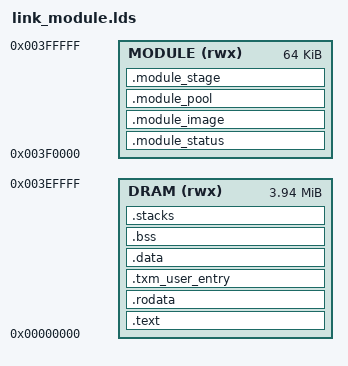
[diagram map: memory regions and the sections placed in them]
/***************************************************************************
 * Copyright (c) 2026 Eclipse ThreadX contributors
 *
 * This program and the accompanying materials are made available under the
 * terms of the MIT License which is available at
 * https://opensource.org/licenses/MIT.
 *
 * AI Disclosure: This file was largely AI-generated by Claude Code (Opus 5).
 * The AI-generated portions may be considered public domain (CC0-1.0)
 * and not subject to the project's licence. The human contributor has
 * reviewed and verified that the code is correct.
 *
 * SPDX-License-Identifier: MIT and CC0-1.0
 **************************************************************************/

/* Link map for the module manager on the Armv8-R AEM FVP (BaseR platform).
 *
 * The BaseR memory map is the Base platform map with its two 2 GB halves
 * swapped: Base DRAM at 0x80000000 appears at 0x00000000 here, and the upper
 * half holds peripherals and is not executable by default.  Code therefore has
 * to be linked into low DRAM -- linking at 0x80000000 produces a silent fault
 * loop with no output.
 *
 * This is the AR1 link.lds with three differences, and each of them is a
 * requirement of the module port rather than a preference.
 *
 *   1.  DRAM stops below a MODULE region.  A module's code and data are handed
 *       to it as MPU regions, and PMSAv8-R has no region priority: two enabled
 *       regions covering one address are CONSTRAINED UNPREDICTABLE.  So module
 *       memory has to be memory no kernel region covers, and the only way to
 *       guarantee that is to end the kernel's data region where the module area
 *       begins.  __data_end__ below is ORIGIN(MODULE) for exactly that reason,
 *       not the "1 MB of heap past the image" the AR1 script uses.
 *
 *   2.  .txm_user_entry sits between the code region and the data region, in a
 *       gap belonging to neither.  It holds the module's gateway into the
 *       kernel, and a module is given a region covering exactly it -- which
 *       would overlap the kernel's code region if it were inside .text.
 *
 *   3.  The MODULE region is subdivided into four fixed pieces.  See each.
 *
 * The two addresses here are also in platform.h as FVP_MODULE_AREA_BASE and
 * FVP_MODULE_AREA_SIZE, because mpu.c programs the manager's load window over
 * the same range.  A linker script cannot include a C header, so the ASSERT at
 * the bottom of this file pins the two spellings together at link time.
 */

ENTRY(_start)

__hyp_stack_size__ = 0x0800;
__svc_stack_size__ = 0x1000;
__irq_stack_size__ = 0x0800;
__fiq_stack_size__ = 0x0400;
__abt_stack_size__ = 0x0400;
__und_stack_size__ = 0x0400;
__sys_stack_size__ = 0x0800;

MEMORY
{
    DRAM   (rwx) : ORIGIN = 0x00000000, LENGTH = 0x003F0000   /* ~4 MB less the module area */
    MODULE (rwx) : ORIGIN = 0x003F0000, LENGTH = 0x00010000   /* 64 KB */
}

SECTIONS
{
    /* PMSAv8-R regions have a 64-byte granule and their limits are inclusive,
       so every boundary the MPU has to describe is aligned to it.  */

    . = ALIGN(64);
    __code_start__ = .;

    .text :
    {
        KEEP(*(.vectors_el2))
        KEEP(*(.vectors_el1))
        *(.text*)
        *(.glue_7)
        *(.glue_7t)
    } > DRAM

    .rodata :
    {
        . = ALIGN(4);
        *(.rodata*)
        . = ALIGN(4);
    } > DRAM

    /* The module's gateway into the kernel.
     *
     * __code_end__ is taken at the START of this section, so the kernel's code
     * region stops just below it: the region limit is __code_end__ - 1, masked
     * down to the granule by PRLAR, and PRLAR's limit is inclusive with the low
     * six bits implied as ones -- so the region ends at __code_end__ - 1 exactly
     * and this section is outside it.  A module gets its own region covering
     * exactly this function, and that region would otherwise overlap the
     * kernel's.
     *
     * Alone in its own section on purpose: anything sharing it would become
     * executable by every module.  ALIGN(64) after the colon aligns the SECTION,
     * which is what is wanted.  Written as ".txm_user_entry ALIGN(64) :" the
     * expression would be the section's ADDRESS instead, and while that form
     * happens to work in a region based at zero, it silently overrides "> DRAM"
     * and is the wrong habit to leave in a file that will be copied.
     */

    .txm_user_entry : ALIGN(64)
    {
        __code_end__ = .;
        __txm_user_entry_start__ = .;
        KEEP(*(.txm_user_entry))
        . = ALIGN(64);
        __txm_user_entry_end__ = .;
    } > DRAM

    .data : ALIGN(64)
    {
        __data_start__ = .;
        *(.data*)
        . = ALIGN(4);
    } > DRAM

    .bss (NOLOAD) :
    {
        . = ALIGN(4);
        __bss_start__ = .;
        *(.bss*)
        *(COMMON)
        . = ALIGN(4);
        __bss_end__ = .;
    } > DRAM

    /* One stack per AArch32 processor mode.  SP must stay 8-byte aligned
       (AAPCS), so each region is aligned before its top symbol is taken.  */

    .stacks (NOLOAD) :
    {
        . = ALIGN(8);
        . = . + __hyp_stack_size__;
        __hyp_stack_top = .;

        . = ALIGN(8);
        . = . + __svc_stack_size__;
        __svc_stack_top = .;

        . = ALIGN(8);
        . = . + __irq_stack_size__;
        __irq_stack_top = .;

        . = ALIGN(8);
        . = . + __fiq_stack_size__;
        __fiq_stack_top = .;

        . = ALIGN(8);
        . = . + __abt_stack_size__;
        __abt_stack_top = .;

        . = ALIGN(8);
        . = . + __und_stack_size__;
        __und_stack_top = .;

        . = ALIGN(8);
        . = . + __sys_stack_size__;
        __sys_stack_top = .;
    } > DRAM

    . = ALIGN(8);
    _end = .;
    PROVIDE(end = .);

    /* ------------------------------------------------------------------
       The module area.  Four pieces, none of which may overlap another:
       each becomes an enabled MPU region while a module runs.
       ------------------------------------------------------------------ */

    /* The shared granules the module reports its progress through, and the one
       it is not allowed to reach.

       The first granule exists because the FVP has no debugger seam.  On
       silicon a GDB harness reads the module's own progress variable out of the
       data area the manager allocated for it; here nothing outside the image
       can read anything, and the manager deliberately knows no symbol of the
       module.  So the manager grants the module a shared MPU region over this
       word and reads it back afterwards, which is what lets the test judge what
       the module managed to do rather than only that it faulted.

       Six granules rather than one, because a module may be granted five shared
       regions and granting a single one exercises only the first entry of the
       five.  Five of these are granted, one granule per entry, and the sixth --
       FVP_MODULE_STATUS_UNGRANTED, index 2, so that a granted granule sits on
       either side of it -- is never granted to anything.  The module writes
       every granted granule, reads them all back, and then writes the gap,
       which must fault.  A limit masked the wrong way or a base off by a
       granule leaks into that gap from one side or the other.

       First in the module area, so the base address is ORIGIN(MODULE) and the
       module can carry it as a constant.  A shared region is a region like any
       other and cannot overlap the image below it, hence whole granules and the
       alignment at the end.  */

    .module_status (NOLOAD) :
    {
        __module_status_start__ = .;
        . = . + 0x180;                  /* six 64-byte granules */
        . = ALIGN(64);
        __module_status_end__ = .;
    } > MODULE

    /* The module image.

       The module is not linked here.  It is built as its own image by the
       fvp_demo_module.elf target, objcopied to a raw binary and included as
       bytes by module_blob.S; this section only decides where those bytes land.
       Keeping the module out of the link is not tidiness: the module library
       defines shims named after the same ThreadX entry points the kernel
       defines, and in one link the shims win, because they arrive as objects and
       the kernel arrives as a static library.  The manager's own service calls
       would then be redirected into the module.  */

    .module_image :
    {
        . = ALIGN(64);
        __module_image_start__ = .;
        KEEP(*(.module_blob))
        . = ALIGN(64);
        __module_image_end__ = .;
    } > MODULE

    /* The pool the manager allocates module data from, in the module area for
       the same reason the image is: whatever the manager hands to a module
       becomes an MPU region, and that region may not overlap a kernel one.

       NOLOAD because nothing is copied in -- the byte pool writes its own
       headers when it is created.  */

    .module_pool (NOLOAD) :
    {
        . = ALIGN(64);
        __module_pool_start__ = .;
        *(.module_pool)
        . = ALIGN(64);
        __module_pool_end__ = .;
    } > MODULE

    /* A second place to load the same module from, which is how this example
       proves the module is relocatable rather than merely built to be.

       A module that runs correctly at the address it was linked for proves
       nothing: the GOT rebase would produce the addresses it started with, and a
       rebase that did nothing would look identical.  So the manager copies the
       blob here and loads it a second time.

       NOLOAD, and deliberately not filled by the linker: if the blob were placed
       here too, a failure to copy would be invisible because the right bytes
       would already be present.  */

    .module_stage (NOLOAD) :
    {
        . = ALIGN(64);
        __module_stage_start__ = .;
        . = . + 0x1000;
        . = ALIGN(64);
        __module_stage_end__ = .;
    } > MODULE

    /* The writable area the MPU describes: data, bss, the stacks and everything
       tx_application_define carves out above _end, ending where the module area
       begins.  Not "_end plus a heap": the kernel's data region has to stop
       below the module area or it overlaps every region a module is given.  */

    __data_end__ = ORIGIN(MODULE);

    /* The image must not have grown into the module area.  Without this the
       overlap appears as a module whose data the kernel also owns, which
       PMSAv8-R reports as an abort from an address that looks perfectly legal. */

    ASSERT(_end <= ORIGIN(MODULE),
           "the manager image has grown into the module area; move FVP_MODULE_AREA_BASE up")

    /* The module carries the status address as a constant and platform.h names
       it as FVP_MODULE_STATUS_BASE.  Neither can see this script, so the
       agreement is pinned here.  The manager checks the same thing again at run
       time, against the symbol, so a build that skipped this file still says so.  */

    ASSERT(__module_status_start__ == 0x003F0000,
           "the module status word is not at FVP_MODULE_STATUS_BASE")

    /* And its size, for the same reason: the manager grants one region per
       granule from this base and the module addresses them by index, so an area
       that is not exactly FVP_MODULE_STATUS_GRANULES granules long would leave
       a grant, or a module write, outside it.  */

    ASSERT(__module_status_end__ - __module_status_start__ == 0x180,
           "the module status area is not FVP_MODULE_STATUS_GRANULES granules long")
}
